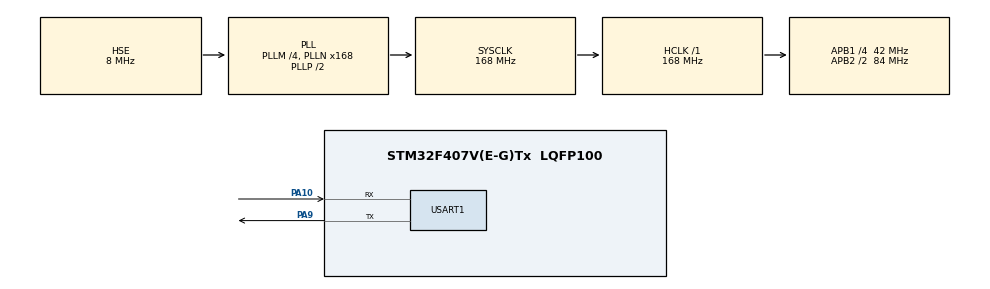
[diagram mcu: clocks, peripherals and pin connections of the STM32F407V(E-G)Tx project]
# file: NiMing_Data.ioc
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Mcu.Family=STM32F4
Mcu.Name=STM32F407V(E-G)Tx
Mcu.Package=LQFP100
NVIC.PriorityGroup=NVIC_PRIORITYGROUP_4
PA10.Mode=Asynchronous
PA10.Signal=USART1_RX
PA13.Mode=Serial_Wire
PA13.Signal=SYS_JTMS-SWDIO
PA14.Mode=Serial_Wire
PA14.Signal=SYS_JTCK-SWCLK
PA9.Mode=Asynchronous
PA9.Signal=USART1_TX
PH0-OSC_IN.Mode=HSE-External-Oscillator
PH0-OSC_IN.Signal=RCC_OSC_IN
PH1-OSC_OUT.Mode=HSE-External-Oscillator
PH1-OSC_OUT.Signal=RCC_OSC_OUT
ProjectManager.HeapSize=0x200
ProjectManager.StackSize=0x400
ProjectManager.TargetToolchain=MDK-ARM V5.27
RCC.48MHZClocksFreq_Value=84000000
RCC.AHBFreq_Value=168000000
RCC.APB1CLKDivider=RCC_HCLK_DIV4
RCC.APB1Freq_Value=42000000
RCC.APB1TimFreq_Value=84000000
RCC.APB2CLKDivider=RCC_HCLK_DIV2
RCC.APB2Freq_Value=84000000
RCC.APB2TimFreq_Value=168000000
RCC.CortexFreq_Value=168000000
RCC.HCLKFreq_Value=168000000
RCC.HSE_VALUE=8000000
RCC.HSI_VALUE=16000000
RCC.LSE_VALUE=32768
RCC.PLLM=4
RCC.PLLN=168
RCC.PLLSourceVirtual=RCC_PLLSOURCE_HSE
RCC.SYSCLKFreq_VALUE=168000000
RCC.SYSCLKSource=RCC_SYSCLKSOURCE_PLLCLK
RCC.VCOOutputFreq_Value=336000000
USART1.VirtualMode=VM_ASYNC
board=custom

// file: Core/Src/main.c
/* USER CODE BEGIN Header */
/**
  ******************************************************************************
  * @file           : main.c
  * @brief          : Main program body
  ******************************************************************************
  * @attention
  *
  * <h2><center>&copy; Copyright (c) 2020 STMicroelectronics.
  * All rights reserved.</center></h2>
  *
  * This software component is licensed by ST under BSD 3-Clause license,
  * the "License"; You may not use this file except in compliance with the
  * License. You may obtain a copy of the License at:
  *                        opensource.org/licenses/BSD-3-Clause
  *
  ******************************************************************************
  */
/* USER CODE END Header */
#include "main.h"
#include "usart.h"
#include "gpio.h"

/* USER CODE BEGIN Includes */
//#include "NiMing.h"
/* USER CODE END Includes */

void SystemClock_Config(void);

/* USER CODE BEGIN 0 */
/*-------匿名上位机串口通信协议---------*/
//数据拆分宏定义   >1字节时拆分发送
#define BYTE0(dwTemp)       (*(char *)(&dwTemp))     //取出int型变量的低字节
#define BYTE1(dwTemp)       (*((char *)(&dwTemp) + 1))     //    取存储在此变量下一内存字节的内容，高字节
#define BYTE2(dwTemp)       (*((char *)(&dwTemp) + 2))
#define BYTE3(dwTemp)       (*((char *)(&dwTemp) + 3))
uint8_t testdatatosend[50];   //发送数据缓冲

void Test_Send_User(int data1, int data2, int data3)	//发送用户数据，这里有3个数据，分别对应本教程3个数据
{
	char _cnt=0;

	testdatatosend[_cnt++]=0xAA;//0xAA为帧头
	testdatatosend[_cnt++]=0x05;//0x05为数据发送源，具体请参考匿名协议，本字节用户可以随意更改
	testdatatosend[_cnt++]=0xAF;//0xAF为数据目的地，AF表示上位机，具体请参考匿名协议
	testdatatosend[_cnt++]=0xF1;//0xF1，表示本帧为F1用户自定义帧，对应高级收码的F1功能帧
	testdatatosend[_cnt++]=0;//本字节表示数据长度，这里先=0，函数最后再赋值，这样就不用人工计算长度了

	testdatatosend[_cnt++]=BYTE1(data1);//将要发送的数据放至发送缓冲区
	testdatatosend[_cnt++]=BYTE0(data1);

	testdatatosend[_cnt++]=BYTE1(data2);//将要发送的数据放至发送缓冲区
	testdatatosend[_cnt++]=BYTE0(data2);

	testdatatosend[_cnt++]=BYTE1(data3);
	testdatatosend[_cnt++]=BYTE0(data3);
	testdatatosend[_cnt++]=BYTE3(data3);
	testdatatosend[_cnt++]=BYTE2(data3);

	testdatatosend[4] = _cnt-5;//_cnt用来计算数据长度，减5为减去帧开头5个非数据字节

	char sum = 0;	//以下为计算sum校验字节，从0xAA也就是首字节，一直到sum字节前一字节
	for(char i=0;i<_cnt;i++)
		sum += testdatatosend[i];

	testdatatosend[_cnt++]=sum;	//将sum校验数据放置最后一字节

	HAL_UART_Transmit(&huart1,testdatatosend,_cnt,100);
}

/* USER CODE END 0 */

int main(void)
{

  /* USER CODE BEGIN 1 */
	int a=0,b=0,c=0;
  /* USER CODE END 1 */

  /* MCU Configuration--------------------------------------------------------*/

  /* Reset of all peripherals, Initializes the Flash interface and the Systick. */
  HAL_Init();

  /* Configure the system clock */
  SystemClock_Config();

  /* Initialize all configured peripherals */
  MX_GPIO_Init();
  MX_USART1_UART_Init();

  /* Infinite loop */
  /* USER CODE BEGIN WHILE */
  while (1)
  {
		a+=1;
		b+=2;
		c+=3;
		Test_Send_User(a,b,c);
		HAL_Delay(100);
    /* USER CODE END WHILE */

  }
}

void SystemClock_Config(void)
{
  RCC_OscInitTypeDef RCC_OscInitStruct = {0};
  RCC_ClkInitTypeDef RCC_ClkInitStruct = {0};

  /** Configure the main internal regulator output voltage
  */
  __HAL_RCC_PWR_CLK_ENABLE();
  __HAL_PWR_VOLTAGESCALING_CONFIG(PWR_REGULATOR_VOLTAGE_SCALE1);
  /** Initializes the RCC Oscillators according to the specified parameters
  * in the RCC_OscInitTypeDef structure.
  */
  RCC_OscInitStruct.OscillatorType = RCC_OSCILLATORTYPE_HSE;
  RCC_OscInitStruct.HSEState = RCC_HSE_ON;
  RCC_OscInitStruct.PLL.PLLState = RCC_PLL_ON;
  RCC_OscInitStruct.PLL.PLLSource = RCC_PLLSOURCE_HSE;
  RCC_OscInitStruct.PLL.PLLM = 4;
  RCC_OscInitStruct.PLL.PLLN = 168;
  RCC_OscInitStruct.PLL.PLLP = RCC_PLLP_DIV2;
  RCC_OscInitStruct.PLL.PLLQ = 4;
  if (HAL_RCC_OscConfig(&RCC_OscInitStruct) != HAL_OK)
  {
    Error_Handler();
  }
  /** Initializes the CPU, AHB and APB buses clocks
  */
  RCC_ClkInitStruct.ClockType = RCC_CLOCKTYPE_HCLK|RCC_CLOCKTYPE_SYSCLK
                              |RCC_CLOCKTYPE_PCLK1|RCC_CLOCKTYPE_PCLK2;
  RCC_ClkInitStruct.SYSCLKSource = RCC_SYSCLKSOURCE_PLLCLK;
  RCC_ClkInitStruct.AHBCLKDivider = RCC_SYSCLK_DIV1;
  RCC_ClkInitStruct.APB1CLKDivider = RCC_HCLK_DIV4;
  RCC_ClkInitStruct.APB2CLKDivider = RCC_HCLK_DIV2;

  if (HAL_RCC_ClockConfig(&RCC_ClkInitStruct, FLASH_LATENCY_5) != HAL_OK)
  {
    Error_Handler();
  }
}

void Error_Handler(void)
{
}

/************************ (C) COPYRIGHT STMicroelectronics *****END OF FILE****/
